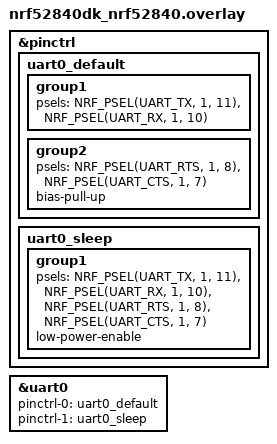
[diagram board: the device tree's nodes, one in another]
&pinctrl {
    uart0_default: uart0_default {
        group1 {
            psels = <NRF_PSEL(UART_TX, 1, 11)>,
                    <NRF_PSEL(UART_RX, 1, 10)>;
        };
        group2 {
            psels = <NRF_PSEL(UART_RTS, 1, 8)>,
                    <NRF_PSEL(UART_CTS, 1, 7)>;
            bias-pull-up;
        };
    };

    uart0_sleep: uart0_sleep {
        group1 {
            psels = <NRF_PSEL(UART_TX, 1, 11)>,
                    <NRF_PSEL(UART_RX, 1, 10)>,
                    <NRF_PSEL(UART_RTS, 1, 8)>,
                    <NRF_PSEL(UART_CTS, 1, 7)>;
            low-power-enable;
        };
    };
};

&uart0 {
    status = "okay";
    pinctrl-0 = <&uart0_default>;
    pinctrl-1 = <&uart0_sleep>;
    pinctrl-names = "default", "sleep";
};
